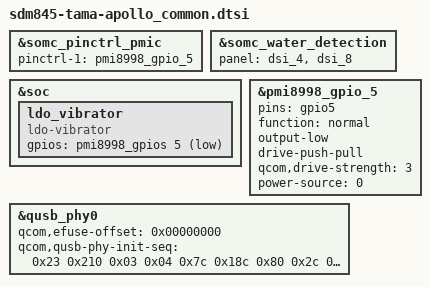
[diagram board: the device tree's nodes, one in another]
// SPDX-License-Identifier: GPL-2.0-only
/*
 * Copyright (c) 2016-2018, The Linux Foundation. All rights reserved.
 */

#include "sdm845-tama-common.dtsi"

&somc_pinctrl_pmic {
	pinctrl-1 = <&pmi8998_gpio_5>;
};

&somc_water_detection {
	panel = <&dsi_4 &dsi_8>;
};


&soc {
	ldo_vibrator {
		compatible = "ldo-vibrator";
		gpios = <&pmi8998_gpios 5 1>;
	};
};

/* GPIO_5: VIB_LDO_EN */
&pmi8998_gpio_5 {
	pins = "gpio5";
	function = "normal";
	/delete-property/ bias-high-impedance;
	output-low;
	drive-push-pull;
	qcom,drive-strength = <3>;
	power-source = <0>;
};

&qusb_phy0 {
	qcom,efuse-offset = <0x00000000>;
	qcom,qusb-phy-init-seq =
		/* <value reg_offset> */
		   <0x23 0x210 /* PWR_CTRL1 */
		    0x03 0x04  /* PLL_ANALOG_CONTROLS_TWO */
		    0x7c 0x18c /* PLL_CLOCK_INVERTERS */
		    0x80 0x2c  /* PLL_CMODE */
		    0x0a 0x184 /* PLL_LOCK_DELAY */
		    0x19 0xb4  /* PLL_DIGITAL_TIMERS_TWO */
		    0x40 0x194 /* PLL_BIAS_CONTROL_1 */
		    0x1a 0x198 /* PLL_BIAS_CONTROL_2 */
		    0x21 0x214 /* PWR_CTRL2 */
		    0x08 0x220 /* IMP_CTRL1 */
		    0x58 0x224 /* IMP_CTRL2 */
		    0x71 0x240 /* TUNE1 */
		    0x2B 0x244 /* TUNE2 */
		    0xca 0x248 /* TUNE3 */
		    0x04 0x24c /* TUNE4 */
		    0x01 0x250 /* TUNE5 */
		    0x00 0x23c /* CHG_CTRL2 */
		    0x22 0x210>; /* PWR_CTRL1 */
};

#include "dsi-panel-apollo.dtsi"
#include "somc-tama-display.dtsi"
#include "somc-tama-display_apollo.dtsi"
#include "somc-tama-touch.dtsi"
#include "somc-tama-touch_apollo.dtsi"
#include "charger-tama-common.dtsi"
#include "charger-tama-apollo.dtsi"
